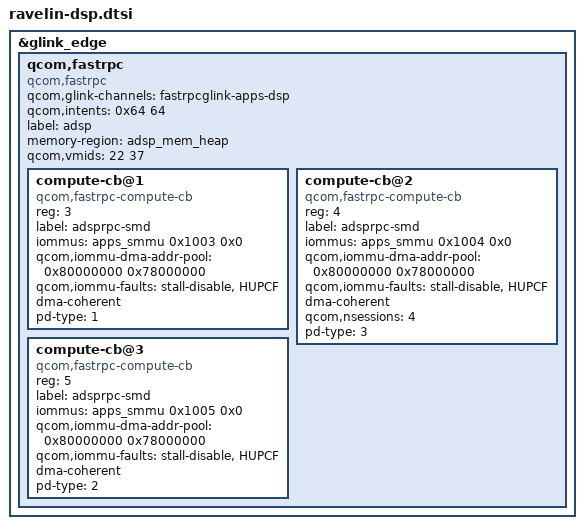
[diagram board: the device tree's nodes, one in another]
// SPDX-License-Identifier: BSD-3-Clause
/*
 * Copyright (c) 2024 Qualcomm Innovation Center, Inc. All rights reserved.
 */
&glink_edge {
	qcom,fastrpc {
		compatible = "qcom,fastrpc";
		qcom,glink-channels = "fastrpcglink-apps-dsp";
		qcom,intents = <0x64 64>;
		label = "adsp";
		memory-region = <&adsp_mem_heap>;
		qcom,vmids = <22 37>;

		compute-cb@1 {
			compatible = "qcom,fastrpc-compute-cb";
			reg = <3>;
			label = "adsprpc-smd";
			iommus = <&apps_smmu 0x1003 0x0>;
			qcom,iommu-dma-addr-pool = <0x80000000 0x78000000>;
			qcom,iommu-faults = "stall-disable", "HUPCF";
			dma-coherent;
			pd-type = <1>;	/* ROOT_PD */
		};

		compute-cb@2 {
			compatible = "qcom,fastrpc-compute-cb";
			reg = <4>;
			label = "adsprpc-smd";
			iommus = <&apps_smmu 0x1004 0x0>;
			qcom,iommu-dma-addr-pool = <0x80000000 0x78000000>;
			qcom,iommu-faults = "stall-disable", "HUPCF";
			dma-coherent;
			qcom,nsessions = <4>;
			pd-type = <3>;	/* SENSORS_STATICPD */
		};

		compute-cb@3 {
			compatible = "qcom,fastrpc-compute-cb";
			reg = <5>;
			label = "adsprpc-smd";
			iommus = <&apps_smmu 0x1005 0x0>;
			qcom,iommu-dma-addr-pool = <0x80000000 0x78000000>;
			qcom,iommu-faults = "stall-disable", "HUPCF";
			dma-coherent;
			pd-type = <2>;	/* AUDIO_STATICPD */
		};
	};
};
